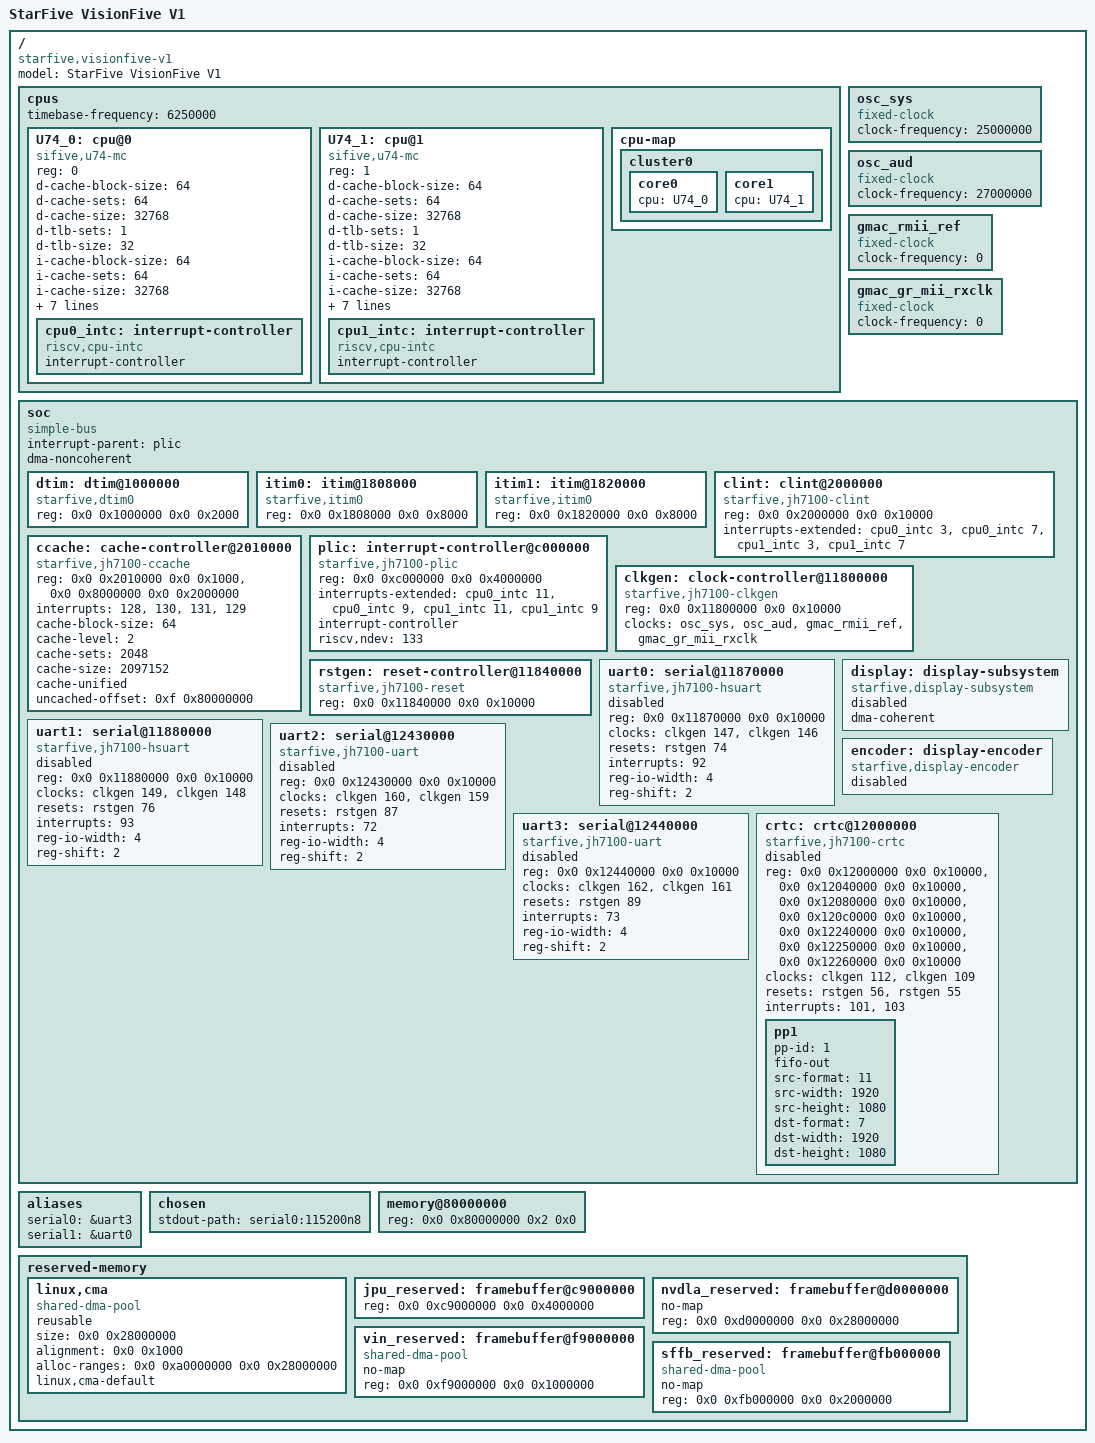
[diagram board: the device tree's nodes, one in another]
/*
 * Copyright (C) 2021 StarFive Technology Co., Ltd.
 * Copyright (C) 2021 Emil Renner Berthing <kernel@esmil.dk>
 *
 * SPDX-License-Identifier: GPL-2.0 OR MIT
 */

/dts-v1/;

/*
 * ToDo:
 *   #include <dt-bindings/clock/starfive-jh7100.h>
 *   #include <dt-bindings/clock/starfive-jh7100-audio.h>
 *   #include <dt-bindings/reset/starfive-jh7100.h>
 *   #include <dt-bindings/reset/starfive-jh7100-audio.h>
 */

/ {
    #address-cells = <2>;
    #size-cells = <2>;

    model = "StarFive VisionFive V1";
    compatible = "starfive,visionfive-v1", "starfive,jh7100";

    cpus {
        #address-cells = <1>;
        #size-cells = <0>;

        U74_0: cpu@0 {
            compatible = "sifive,u74-mc", "riscv";
            reg = <0>;
            d-cache-block-size = <64>;
            d-cache-sets = <64>;
            d-cache-size = <32768>;
            d-tlb-sets = <1>;
            d-tlb-size = <32>;
            device_type = "cpu";
            i-cache-block-size = <64>;
            i-cache-sets = <64>;
            i-cache-size = <32768>;
            i-tlb-sets = <1>;
            i-tlb-size = <32>;
            mmu-type = "riscv,sv39";
            next-level-cache = <&ccache>;
            riscv,isa = "rv64imafdc";
            starfive,itim = <&itim0>;
            tlb-split;

            cpu0_intc: interrupt-controller {
                compatible = "riscv,cpu-intc";
                interrupt-controller;
                #interrupt-cells = <1>;
            };
        };

        U74_1: cpu@1 {
            compatible = "sifive,u74-mc", "riscv";
            reg = <1>;
            d-cache-block-size = <64>;
            d-cache-sets = <64>;
            d-cache-size = <32768>;
            d-tlb-sets = <1>;
            d-tlb-size = <32>;
            device_type = "cpu";
            i-cache-block-size = <64>;
            i-cache-sets = <64>;
            i-cache-size = <32768>;
            i-tlb-sets = <1>;
            i-tlb-size = <32>;
            mmu-type = "riscv,sv39";
            next-level-cache = <&ccache>;
            riscv,isa = "rv64imafdc";
            starfive,itim = <&itim1>;
            tlb-split;

            cpu1_intc: interrupt-controller {
                compatible = "riscv,cpu-intc";
                interrupt-controller;
                #interrupt-cells = <1>;
            };
        };

        cpu-map {
            cluster0 {
                core0 {
                    cpu = <&U74_0>;
                };

                core1 {
                    cpu = <&U74_1>;
                };
            };
        };
    };

    osc_sys: osc_sys {
        compatible = "fixed-clock";
        #clock-cells = <0>;
        clock-frequency = <25000000>;
    };

    osc_aud: osc_aud {
        compatible = "fixed-clock";
        #clock-cells = <0>;
        clock-frequency = <27000000>;
    };

    gmac_rmii_ref: gmac_rmii_ref {
        compatible = "fixed-clock";
        #clock-cells = <0>;
        /* Should be overridden by the board when needed */
        clock-frequency = <0>;
    };

    gmac_gr_mii_rxclk: gmac_gr_mii_rxclk {
        compatible = "fixed-clock";
        #clock-cells = <0>;
        /* Should be overridden by the board when needed */
        clock-frequency = <0>;
    };

    soc {
        compatible = "simple-bus";
        interrupt-parent = <&plic>;
        dma-noncoherent;
        #address-cells = <2>;
        #size-cells = <2>;
        ranges;

        dtim: dtim@1000000 {
            compatible = "starfive,dtim0";
            reg = <0x0 0x1000000 0x0 0x2000>;
            reg-names = "mem";
        };

        itim0: itim@1808000 {
            compatible = "starfive,itim0";
            reg = <0x0 0x1808000 0x0 0x8000>;
            reg-names = "mem";
        };

        itim1: itim@1820000 {
            compatible = "starfive,itim0";
            reg = <0x0 0x1820000 0x0 0x8000>;
            reg-names = "mem";
        };

        clint: clint@2000000 {
            compatible = "starfive,jh7100-clint", "sifive,clint0";
            reg = <0x0 0x2000000 0x0 0x10000>;
            interrupts-extended = <&cpu0_intc 3>, <&cpu0_intc 7>,
                          <&cpu1_intc 3>, <&cpu1_intc 7>;
        };

        ccache: cache-controller@2010000 {
            compatible = "starfive,jh7100-ccache", "cache";
            reg = <0x0 0x2010000 0x0 0x1000>,
                  <0x0 0x8000000 0x0 0x2000000>;
            reg-names = "control", "sideband";
            interrupts = <128>, <130>, <131>, <129>;
            cache-block-size = <64>;
            cache-level = <2>;
            cache-sets = <2048>;
            cache-size = <2097152>;
            cache-unified;
            /*next-level-cache = <&L40 &L36>;*/
            uncached-offset = <0xf 0x80000000>;
        };

        plic: interrupt-controller@c000000 {
            compatible = "starfive,jh7100-plic", "sifive,plic-1.0.0";
            reg = <0x0 0xc000000 0x0 0x4000000>;
            interrupts-extended = <&cpu0_intc 11>, <&cpu0_intc 9>,
                          <&cpu1_intc 11>, <&cpu1_intc 9>;
            interrupt-controller;
            #address-cells = <0>;
            #interrupt-cells = <1>;
            riscv,ndev = <133>;
        };

        clkgen: clock-controller@11800000 {
            compatible = "starfive,jh7100-clkgen";
            reg = <0x0 0x11800000 0x0 0x10000>;
            clocks = <&osc_sys>, <&osc_aud>, <&gmac_rmii_ref>, <&gmac_gr_mii_rxclk>;
            clock-names = "osc_sys", "osc_aud", "gmac_rmii_ref", "gmac_gr_mii_rxclk";
            #clock-cells = <1>;
        };

        rstgen: reset-controller@11840000 {
            compatible = "starfive,jh7100-reset";
            reg = <0x0 0x11840000 0x0 0x10000>;
            #reset-cells = <1>;
        };

        uart0: serial@11870000 {
            compatible = "starfive,jh7100-hsuart", "snps,dw-apb-uart";
            reg = <0x0 0x11870000 0x0 0x10000>;
            clocks = <&clkgen 147>, /* JH7100_CLK_UART0_CORE */
                 <&clkgen 146>; /* JH7100_CLK_UART0_APB */
            clock-names = "baudclk", "apb_pclk";
            resets = <&rstgen 74>; /* JH7100_RSTN_UART0_APB */
            interrupts = <92>;
            reg-io-width = <4>;
            reg-shift = <2>;
            status = "disabled";
        };

        uart1: serial@11880000 {
            compatible = "starfive,jh7100-hsuart", "snps,dw-apb-uart";
            reg = <0x0 0x11880000 0x0 0x10000>;
            clocks = <&clkgen 149>, /* JH7100_CLK_UART1_CORE */
                 <&clkgen 148>; /* JH7100_CLK_UART1_APB */
            clock-names = "baudclk", "apb_pclk";
            resets = <&rstgen 76>; /* JH7100_RSTN_UART1_APB */
            interrupts = <93>;
            reg-io-width = <4>;
            reg-shift = <2>;
            status = "disabled";
        };

        uart2: serial@12430000 {
            compatible = "starfive,jh7100-uart", "snps,dw-apb-uart";
            reg = <0x0 0x12430000 0x0 0x10000>;
            clocks = <&clkgen 160>, /* JH7100_CLK_UART2_CORE */
                 <&clkgen 159>; /* JH7100_CLK_UART2_APB */
            clock-names = "baudclk", "apb_pclk";
            resets = <&rstgen 87>; /* JH7100_RSTN_UART2_APB */
            interrupts = <72>;
            reg-io-width = <4>;
            reg-shift = <2>;
            status = "disabled";
        };

        uart3: serial@12440000 {
            compatible = "starfive,jh7100-uart", "snps,dw-apb-uart";
            reg = <0x0 0x12440000 0x0 0x10000>;
            clocks = <&clkgen 162>, /* JH7100_CLK_UART3_CORE */
                 <&clkgen 161>; /* JH7100_CLK_UART3_APB */
            clock-names = "baudclk", "apb_pclk";
            resets = <&rstgen 89>; /* JH7100_RSTN_UART3_APB */
            interrupts = <73>;
            reg-io-width = <4>;
            reg-shift = <2>;
            status = "disabled";
        };


        display: display-subsystem {
            compatible = "starfive,display-subsystem";
            dma-coherent;
            status = "disabled";
        };

        encoder: display-encoder {
            compatible = "starfive,display-encoder";
            status = "disabled";
        };

        crtc: crtc@12000000 {
            compatible = "starfive,jh7100-crtc";
            reg = <0x0 0x12000000 0x0 0x10000>,
                  <0x0 0x12040000 0x0 0x10000>,
                  <0x0 0x12080000 0x0 0x10000>,
                  <0x0 0x120c0000 0x0 0x10000>,
                  <0x0 0x12240000 0x0 0x10000>,
                  <0x0 0x12250000 0x0 0x10000>,
                  <0x0 0x12260000 0x0 0x10000>;
            reg-names = "lcdc", "vpp0", "vpp1", "vpp2", "clk", "rst", "sys";
            clocks = <&clkgen 112>, <&clkgen 109>; /* JH7100_CLK_DISP_AXI, JH7100_CLK_VOUT_SRC */
            clock-names = "disp_axi", "vout_src";
            resets = <&rstgen 56>, <&rstgen 55>; /* JH7100_RSTN_DISP_AXI, JH7100_RSTN_VOUT_SRC */
            reset-names = "disp_axi", "vout_src";
            interrupts = <101>, <103>;
            interrupt-names = "lcdc_irq", "vpp1_irq";
            #address-cells = <1>;
            #size-cells = <0>;
            status = "disabled";

            pp1 {
                pp-id = <1>;
                fifo-out;
                //sys-bus-out;
                src-format = <11>; //<COLOR_RGB565>;
                src-width = <1920>;
                src-height = <1080>;
                dst-format = <7>; //<COLOR_RGB888_ARGB>;
                dst-width = <1920>;
                dst-height = <1080>;
            };
        };

    };
};

/*
 * #include <dt-bindings/gpio/gpio.h>
 * #include <dt-bindings/leds/common.h>
 * #include <dt-bindings/pinctrl/pinctrl-starfive-jh7100.h>
 */

/ {
    aliases {
        /* mmc0 = &sdio0; */
        /* mmc1 = &sdio1; */
        serial0 = &uart3;
        serial1 = &uart0;
    };

    chosen {
        stdout-path = "serial0:115200n8";
    };

    cpus {
        timebase-frequency = <6250000>;
    };

    memory@80000000 {
        device_type = "memory";
        reg = <0x0 0x80000000 0x2 0x0>;
    };

    reserved-memory {
        #address-cells = <2>;
        #size-cells = <2>;
        ranges;

        linux,cma {
            compatible = "shared-dma-pool";
            reusable;
            size = <0x0 0x28000000>;
            alignment = <0x0 0x1000>;
            alloc-ranges = <0x0 0xa0000000 0x0 0x28000000>;
            linux,cma-default;
        };

        jpu_reserved: framebuffer@c9000000 {
            reg = <0x0 0xc9000000 0x0 0x4000000>;
        };

        nvdla_reserved: framebuffer@d0000000 {
            no-map;
            reg = <0x0 0xd0000000 0x0 0x28000000>;
        };

        vin_reserved: framebuffer@f9000000 {
            compatible = "shared-dma-pool";
            no-map;
            reg = <0x0 0xf9000000 0x0 0x1000000>;
        };

        sffb_reserved: framebuffer@fb000000 {
            compatible = "shared-dma-pool";
            no-map;
            reg = <0x0 0xfb000000 0x0 0x2000000>;
        };
    };

};
